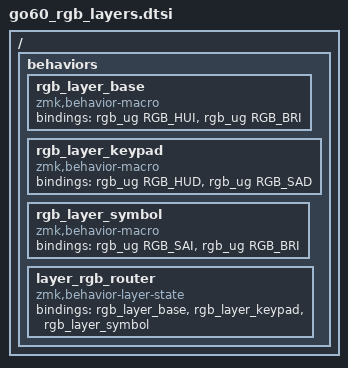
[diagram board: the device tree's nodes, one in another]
#include <dt-bindings/zmk/rgb.h>

/ {
    behaviors {

        /* =========================
         * CAPA BASE
         * ========================= */
        rgb_layer_base: rgb_layer_base {
            compatible = "zmk,behavior-macro";
            #binding-cells = <0>;

            bindings =
                <&rgb_ug RGB_HUI>,   /* amarillo */
                <&rgb_ug RGB_BRI>;
        };

        /* =========================
         * KEYPAD
         * ========================= */
        rgb_layer_keypad: rgb_layer_keypad {
            compatible = "zmk,behavior-macro";
            #binding-cells = <0>;

            bindings =
                <&rgb_ug RGB_HUD>,   /* azul */
                <&rgb_ug RGB_SAD>;
        };

        /* =========================
         * SYMBOL NAV
         * ========================= */
        rgb_layer_symbol: rgb_layer_symbol {
            compatible = "zmk,behavior-macro";
            #binding-cells = <0>;

            bindings =
                <&rgb_ug RGB_SAI>,   /* verde */
                <&rgb_ug RGB_BRI>;
        };
    };

    /* =========================
     * LINK LAYER STATE → RGB
     * ========================= */
    behaviors {
        layer_rgb_router: layer_rgb_router {
            compatible = "zmk,behavior-layer-state";
            #binding-cells = <1>;

            bindings =
                <&rgb_layer_base>,
                <&rgb_layer_keypad>,
                <&rgb_layer_symbol>;
        };
    };
};
